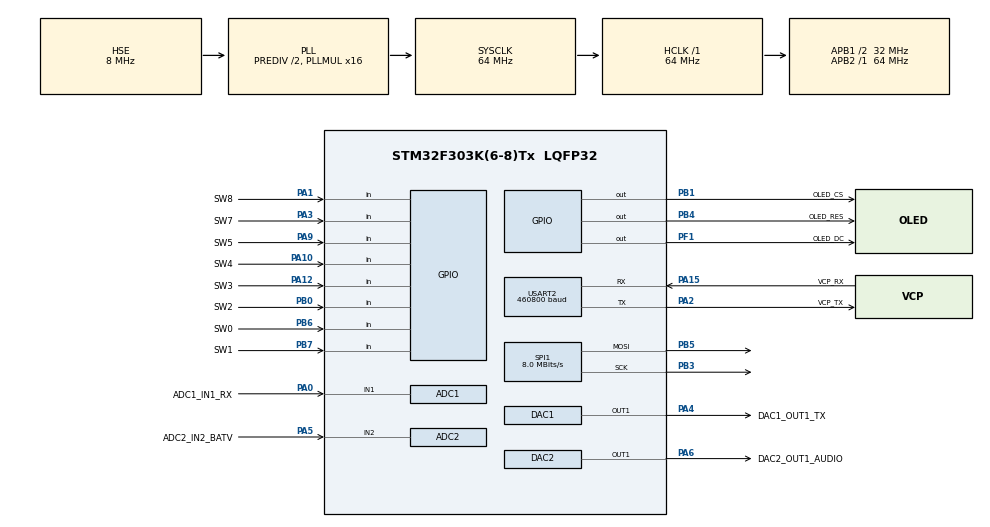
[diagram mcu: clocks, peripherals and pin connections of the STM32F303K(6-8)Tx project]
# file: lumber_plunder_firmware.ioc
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ADC1.Channel-0\#ChannelRegularConversion=ADC_CHANNEL_1
ADC1.Channel-1\#ChannelRegularConversion=ADC_CHANNEL_1
ADC1.Channel-10\#ChannelRegularConversion=ADC_CHANNEL_1
ADC1.Channel-11\#ChannelRegularConversion=ADC_CHANNEL_1
ADC1.Channel-12\#ChannelRegularConversion=ADC_CHANNEL_1
ADC1.Channel-13\#ChannelRegularConversion=ADC_CHANNEL_1
ADC1.Channel-14\#ChannelRegularConversion=ADC_CHANNEL_1
ADC1.Channel-15\#ChannelRegularConversion=ADC_CHANNEL_1
ADC1.Channel-2\#ChannelRegularConversion=ADC_CHANNEL_1
ADC1.Channel-3\#ChannelRegularConversion=ADC_CHANNEL_1
ADC1.Channel-4\#ChannelRegularConversion=ADC_CHANNEL_1
ADC1.Channel-5\#ChannelRegularConversion=ADC_CHANNEL_1
ADC1.Channel-6\#ChannelRegularConversion=ADC_CHANNEL_1
ADC1.Channel-7\#ChannelRegularConversion=ADC_CHANNEL_1
ADC1.Channel-8\#ChannelRegularConversion=ADC_CHANNEL_1
ADC1.Channel-9\#ChannelRegularConversion=ADC_CHANNEL_1
ADC1.NbrOfConversion=16
ADC1.NbrOfConversionFlag=1
ADC1.Offset-0\#ChannelRegularConversion=0
ADC1.Offset-1\#ChannelRegularConversion=0
ADC1.Offset-10\#ChannelRegularConversion=0
ADC1.Offset-11\#ChannelRegularConversion=0
ADC1.Offset-12\#ChannelRegularConversion=0
ADC1.Offset-13\#ChannelRegularConversion=0
ADC1.Offset-14\#ChannelRegularConversion=0
ADC1.Offset-15\#ChannelRegularConversion=0
ADC1.Offset-2\#ChannelRegularConversion=0
ADC1.Offset-3\#ChannelRegularConversion=0
ADC1.Offset-4\#ChannelRegularConversion=0
ADC1.Offset-5\#ChannelRegularConversion=0
ADC1.Offset-6\#ChannelRegularConversion=0
ADC1.Offset-7\#ChannelRegularConversion=0
ADC1.Offset-8\#ChannelRegularConversion=0
ADC1.Offset-9\#ChannelRegularConversion=0
ADC1.OffsetNumber-0\#ChannelRegularConversion=ADC_OFFSET_NONE
ADC1.OffsetNumber-1\#ChannelRegularConversion=ADC_OFFSET_NONE
ADC1.OffsetNumber-10\#ChannelRegularConversion=ADC_OFFSET_NONE
ADC1.OffsetNumber-11\#ChannelRegularConversion=ADC_OFFSET_NONE
ADC1.OffsetNumber-12\#ChannelRegularConversion=ADC_OFFSET_NONE
ADC1.OffsetNumber-13\#ChannelRegularConversion=ADC_OFFSET_NONE
ADC1.OffsetNumber-14\#ChannelRegularConversion=ADC_OFFSET_NONE
ADC1.OffsetNumber-15\#ChannelRegularConversion=ADC_OFFSET_NONE
ADC1.OffsetNumber-2\#ChannelRegularConversion=ADC_OFFSET_NONE
ADC1.OffsetNumber-3\#ChannelRegularConversion=ADC_OFFSET_NONE
ADC1.OffsetNumber-4\#ChannelRegularConversion=ADC_OFFSET_NONE
ADC1.OffsetNumber-5\#ChannelRegularConversion=ADC_OFFSET_NONE
ADC1.OffsetNumber-6\#ChannelRegularConversion=ADC_OFFSET_NONE
ADC1.OffsetNumber-7\#ChannelRegularConversion=ADC_OFFSET_NONE
ADC1.OffsetNumber-8\#ChannelRegularConversion=ADC_OFFSET_NONE
ADC1.OffsetNumber-9\#ChannelRegularConversion=ADC_OFFSET_NONE
ADC1.Rank-0\#ChannelRegularConversion=1
ADC1.Rank-1\#ChannelRegularConversion=2
ADC1.Rank-10\#ChannelRegularConversion=11
ADC1.Rank-11\#ChannelRegularConversion=12
ADC1.Rank-12\#ChannelRegularConversion=13
ADC1.Rank-13\#ChannelRegularConversion=14
ADC1.Rank-14\#ChannelRegularConversion=15
ADC1.Rank-15\#ChannelRegularConversion=16
ADC1.Rank-2\#ChannelRegularConversion=3
ADC1.Rank-3\#ChannelRegularConversion=4
ADC1.Rank-4\#ChannelRegularConversion=5
ADC1.Rank-5\#ChannelRegularConversion=6
ADC1.Rank-6\#ChannelRegularConversion=7
ADC1.Rank-7\#ChannelRegularConversion=8
ADC1.Rank-8\#ChannelRegularConversion=9
ADC1.Rank-9\#ChannelRegularConversion=10
ADC1.SamplingTime-0\#ChannelRegularConversion=ADC_SAMPLETIME_1CYCLE_5
ADC1.SamplingTime-1\#ChannelRegularConversion=ADC_SAMPLETIME_1CYCLE_5
ADC1.SamplingTime-10\#ChannelRegularConversion=ADC_SAMPLETIME_1CYCLE_5
ADC1.SamplingTime-11\#ChannelRegularConversion=ADC_SAMPLETIME_1CYCLE_5
ADC1.SamplingTime-12\#ChannelRegularConversion=ADC_SAMPLETIME_1CYCLE_5
ADC1.SamplingTime-13\#ChannelRegularConversion=ADC_SAMPLETIME_1CYCLE_5
ADC1.SamplingTime-14\#ChannelRegularConversion=ADC_SAMPLETIME_1CYCLE_5
ADC1.SamplingTime-15\#ChannelRegularConversion=ADC_SAMPLETIME_1CYCLE_5
ADC1.SamplingTime-2\#ChannelRegularConversion=ADC_SAMPLETIME_1CYCLE_5
ADC1.SamplingTime-3\#ChannelRegularConversion=ADC_SAMPLETIME_1CYCLE_5
ADC1.SamplingTime-4\#ChannelRegularConversion=ADC_SAMPLETIME_1CYCLE_5
ADC1.SamplingTime-5\#ChannelRegularConversion=ADC_SAMPLETIME_1CYCLE_5
ADC1.SamplingTime-6\#ChannelRegularConversion=ADC_SAMPLETIME_1CYCLE_5
ADC1.SamplingTime-7\#ChannelRegularConversion=ADC_SAMPLETIME_1CYCLE_5
ADC1.SamplingTime-8\#ChannelRegularConversion=ADC_SAMPLETIME_1CYCLE_5
ADC1.SamplingTime-9\#ChannelRegularConversion=ADC_SAMPLETIME_1CYCLE_5
ADC1.SamplingTimeOPAMP-0\#ChannelRegularConversion=ADC_SAMPLETIME_19CYCLES_5
ADC1.SamplingTimeOPAMP-1\#ChannelRegularConversion=ADC_SAMPLETIME_1CYCLE_5
ADC1.SamplingTimeOPAMP-10\#ChannelRegularConversion=ADC_SAMPLETIME_1CYCLE_5
ADC1.SamplingTimeOPAMP-11\#ChannelRegularConversion=ADC_SAMPLETIME_1CYCLE_5
ADC1.SamplingTimeOPAMP-12\#ChannelRegularConversion=ADC_SAMPLETIME_1CYCLE_5
ADC1.SamplingTimeOPAMP-13\#ChannelRegularConversion=ADC_SAMPLETIME_1CYCLE_5
ADC1.SamplingTimeOPAMP-14\#ChannelRegularConversion=ADC_SAMPLETIME_1CYCLE_5
ADC1.SamplingTimeOPAMP-15\#ChannelRegularConversion=ADC_SAMPLETIME_1CYCLE_5
ADC1.SamplingTimeOPAMP-2\#ChannelRegularConversion=ADC_SAMPLETIME_1CYCLE_5
ADC1.SamplingTimeOPAMP-3\#ChannelRegularConversion=ADC_SAMPLETIME_1CYCLE_5
ADC1.SamplingTimeOPAMP-4\#ChannelRegularConversion=ADC_SAMPLETIME_1CYCLE_5
ADC1.SamplingTimeOPAMP-5\#ChannelRegularConversion=ADC_SAMPLETIME_1CYCLE_5
ADC1.SamplingTimeOPAMP-6\#ChannelRegularConversion=ADC_SAMPLETIME_1CYCLE_5
ADC1.SamplingTimeOPAMP-7\#ChannelRegularConversion=ADC_SAMPLETIME_1CYCLE_5
ADC1.SamplingTimeOPAMP-8\#ChannelRegularConversion=ADC_SAMPLETIME_1CYCLE_5
ADC1.SamplingTimeOPAMP-9\#ChannelRegularConversion=ADC_SAMPLETIME_1CYCLE_5
ADC1.SubFamily=STM32F303x8
ADC1.master=1
ADC2.Channel-17\#ChannelRegularConversion=ADC_CHANNEL_2
ADC2.NbrOfConversionFlag=1
ADC2.Offset-17\#ChannelRegularConversion=0
ADC2.OffsetNumber-17\#ChannelRegularConversion=ADC_OFFSET_NONE
ADC2.Rank-17\#ChannelRegularConversion=1
ADC2.SamplingTime-17\#ChannelRegularConversion=ADC_SAMPLETIME_1CYCLE_5
ADC2.SamplingTimeOPAMP-17\#ChannelRegularConversion=ADC_SAMPLETIME_1CYCLE_5
ADC2.SubFamily=STM32F303x8
DAC1.DAC_OutputBuffer=DAC_OUTPUTBUFFER_ENABLE
Dma.DAC1_CH1.0.Direction=DMA_MEMORY_TO_PERIPH
Dma.DAC1_CH1.0.Instance=DMA1_Channel3
Dma.DAC1_CH1.0.MemDataAlignment=DMA_MDATAALIGN_HALFWORD
Dma.DAC1_CH1.0.MemInc=DMA_MINC_ENABLE
Dma.DAC1_CH1.0.Mode=DMA_CIRCULAR
Dma.DAC1_CH1.0.PeriphDataAlignment=DMA_PDATAALIGN_HALFWORD
Dma.DAC1_CH1.0.PeriphInc=DMA_PINC_DISABLE
Dma.DAC1_CH1.0.Priority=DMA_PRIORITY_HIGH
Dma.Request0=DAC1_CH1
Mcu.Family=STM32F3
Mcu.Name=STM32F303K(6-8)Tx
Mcu.Package=LQFP32
NVIC.DMA1_Channel3_IRQn=true\:0\:0\:false\:false\:true\:false\:true\:true
NVIC.PriorityGroup=NVIC_PRIORITYGROUP_4
PA0.GPIO_Label=ADC1_IN1_RX
PA0.Mode=IN1-Single-Ended
PA0.Signal=ADC1_IN1
PA1.GPIO_Label=SW8
PA1.Signal=GPIO_Input
PA10.GPIO_Label=SW4
PA10.Signal=GPIO_Input
PA12.GPIO_Label=SW3
PA12.Signal=GPIO_Input
PA13.GPIO_Label=SWDIO
PA13.Mode=Serial_Wire
PA13.Signal=SYS_JTMS-SWDIO
PA14.GPIO_Label=SWCLK
PA14.Mode=Serial_Wire
PA14.Signal=SYS_JTCK-SWCLK
PA15.GPIO_Label=VCP_RX
PA15.Mode=Asynchronous
PA15.Signal=USART2_RX
PA2.GPIO_Label=VCP_TX
PA2.Mode=Asynchronous
PA2.Signal=USART2_TX
PA3.GPIO_Label=SW7
PA3.Signal=GPIO_Input
PA4.GPIO_Label=DAC1_OUT1_TX
PA4.Signal=COMP_DAC11_group
PA5.GPIO_Label=ADC2_IN2_BATV
PA5.Mode=IN2-Single-Ended
PA5.Signal=ADC2_IN2
PA6.GPIO_Label=DAC2_OUT1_AUDIO
PA6.Signal=COMP_DAC21_group
PA7.Signal=ADC2_IN4
PA9.GPIO_Label=SW5
PA9.Signal=GPIO_Input
PB0.GPIO_Label=SW2
PB0.Signal=GPIO_Input
PB1.GPIO_Label=OLED_CS
PB1.Signal=GPIO_Output
PB3.Mode=TX_Only_Simplex_Unidirect_Master
PB3.Signal=SPI1_SCK
PB4.GPIO_Label=OLED_RES
PB4.Signal=GPIO_Output
PB5.Mode=TX_Only_Simplex_Unidirect_Master
PB5.Signal=SPI1_MOSI
PB6.GPIO_Label=SW0
PB6.Signal=GPIO_Input
PB7.GPIO_Label=SW1
PB7.Signal=GPIO_Input
PF0\ /\ OSC_IN.GPIO_Label=MCO
PF0\ /\ OSC_IN.Mode=HSE-External-Clock-Source
PF0\ /\ OSC_IN.Signal=RCC_OSC_IN
PF1\ /\ OSC_OUT.GPIO_Label=OLED_DC
PF1\ /\ OSC_OUT.Signal=GPIO_Output
ProjectManager.HeapSize=0x200
ProjectManager.StackSize=0x400
ProjectManager.TargetToolchain=STM32CubeIDE
RCC.ADC12PRES=RCC_ADC12PLLCLK_DIV64
RCC.AHBFreq_Value=64000000
RCC.APB1CLKDivider=RCC_HCLK_DIV2
RCC.APB1Freq_Value=32000000
RCC.APB1TimFreq_Value=64000000
RCC.APB2Freq_Value=64000000
RCC.APB2TimFreq_Value=64000000
RCC.CortexFreq_Value=64000000
RCC.HCLKFreq_Value=64000000
RCC.HSE_VALUE=8000000
RCC.HSI_VALUE=8000000
RCC.PLLMUL=RCC_PLL_MUL16
RCC.PLLSourceVirtual=RCC_PLLSOURCE_HSE
RCC.RCC_PLLsource_Clock_Source_FROM_HSE=RCC_HSE_PREDIV_DIV2
RCC.SYSCLKFreq_VALUE=64000000
RCC.SYSCLKSourceVirtual=RCC_SYSCLKSOURCE_PLLCLK
SH.COMP_DAC11_group.0=DAC1_OUT1,DAC_OUT1
SH.COMP_DAC21_group.0=DAC2_OUT1,Switch_Enable_OUT1
SPI1.BaudRatePrescaler=SPI_BAUDRATEPRESCALER_8
SPI1.CLKPhase=SPI_PHASE_1EDGE
SPI1.CLKPolarity=SPI_POLARITY_LOW
SPI1.CalculateBaudRate=8.0 MBits/s
SPI1.DataSize=SPI_DATASIZE_8BIT
SPI1.Direction=SPI_DIRECTION_2LINES
SPI1.FirstBit=SPI_FIRSTBIT_MSB
SPI1.Mode=SPI_MODE_MASTER
SPI1.VirtualType=VM_MASTER
USART2.BaudRate=460800
USART2.VirtualMode-Asynchronous=VM_ASYNC
board=NUCLEO-F303K8

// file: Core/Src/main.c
/* USER CODE BEGIN Header */
/**
  ******************************************************************************
  * @file           : main.c
  * @brief          : Main program body
  ******************************************************************************
  * @attention
  *
  * Copyright (c) 2023 STMicroelectronics.
  * All rights reserved.
  *
  * This software is licensed under terms that can be found in the LICENSE file
  * in the root directory of this software component.
  * If no LICENSE file comes with this software, it is provided AS-IS.
  *
  ******************************************************************************
  */
/* USER CODE END Header */
#include "main.h"

ADC_HandleTypeDef hadc1;

DAC_HandleTypeDef hdac1;
DAC_HandleTypeDef hdac2;
DMA_HandleTypeDef hdma_dac1_ch1;

SPI_HandleTypeDef hspi1;

UART_HandleTypeDef huart2;

void SystemClock_Config(void);
static void MX_GPIO_Init(void);
static void MX_DMA_Init(void);
static void MX_USART2_UART_Init(void);
static void MX_ADC1_Init(void);
static void MX_SPI1_Init(void);
static void MX_ADC2_Init(void);
static void MX_DAC1_Init(void);
static void MX_DAC2_Init(void);

int main(void)
{

  /* MCU Configuration--------------------------------------------------------*/

  /* Reset of all peripherals, Initializes the Flash interface and the Systick. */
  HAL_Init();

  /* Configure the system clock */
  SystemClock_Config();

  /* Initialize all configured peripherals */
  MX_GPIO_Init();
  MX_DMA_Init();
  MX_USART2_UART_Init();
  MX_ADC1_Init();
  MX_SPI1_Init();
  MX_ADC2_Init();
  MX_DAC1_Init();
  MX_DAC2_Init();
  /* USER CODE BEGIN 2 */

  //The only non-generated code in this file... everything else is handled in maincpp.c
  maincpp();

  /* USER CODE END 2 */

  /* Infinite loop */

}

void SystemClock_Config(void)
{
  RCC_OscInitTypeDef RCC_OscInitStruct = {0};
  RCC_ClkInitTypeDef RCC_ClkInitStruct = {0};
  RCC_PeriphCLKInitTypeDef PeriphClkInit = {0};

  /** Initializes the RCC Oscillators according to the specified parameters
  * in the RCC_OscInitTypeDef structure.
  */
  RCC_OscInitStruct.OscillatorType = RCC_OSCILLATORTYPE_HSE;
  RCC_OscInitStruct.HSEState = RCC_HSE_BYPASS;
  RCC_OscInitStruct.HSEPredivValue = RCC_HSE_PREDIV_DIV2;
  RCC_OscInitStruct.HSIState = RCC_HSI_ON;
  RCC_OscInitStruct.PLL.PLLState = RCC_PLL_ON;
  RCC_OscInitStruct.PLL.PLLSource = RCC_PLLSOURCE_HSE;
  RCC_OscInitStruct.PLL.PLLMUL = RCC_PLL_MUL16;
  if (HAL_RCC_OscConfig(&RCC_OscInitStruct) != HAL_OK)
  {
    Error_Handler();
  }

  /** Initializes the CPU, AHB and APB buses clocks
  */
  RCC_ClkInitStruct.ClockType = RCC_CLOCKTYPE_HCLK|RCC_CLOCKTYPE_SYSCLK
                              |RCC_CLOCKTYPE_PCLK1|RCC_CLOCKTYPE_PCLK2;
  RCC_ClkInitStruct.SYSCLKSource = RCC_SYSCLKSOURCE_PLLCLK;
  RCC_ClkInitStruct.AHBCLKDivider = RCC_SYSCLK_DIV1;
  RCC_ClkInitStruct.APB1CLKDivider = RCC_HCLK_DIV2;
  RCC_ClkInitStruct.APB2CLKDivider = RCC_HCLK_DIV1;

  if (HAL_RCC_ClockConfig(&RCC_ClkInitStruct, FLASH_LATENCY_2) != HAL_OK)
  {
    Error_Handler();
  }
  PeriphClkInit.PeriphClockSelection = RCC_PERIPHCLK_ADC12;
  PeriphClkInit.Adc12ClockSelection = RCC_ADC12PLLCLK_DIV64;
  if (HAL_RCCEx_PeriphCLKConfig(&PeriphClkInit) != HAL_OK)
  {
    Error_Handler();
  }
}

static void MX_ADC1_Init(void)
{

  ADC_MultiModeTypeDef multimode = {0};
  ADC_ChannelConfTypeDef sConfig = {0};

  /** Common config
  */
  hadc1.Instance = ADC1;
  hadc1.Init.ClockPrescaler = ADC_CLOCK_ASYNC_DIV1;
  hadc1.Init.Resolution = ADC_RESOLUTION_12B;
  hadc1.Init.ScanConvMode = ADC_SCAN_ENABLE;
  hadc1.Init.ContinuousConvMode = DISABLE;
  hadc1.Init.DiscontinuousConvMode = DISABLE;
  hadc1.Init.ExternalTrigConvEdge = ADC_EXTERNALTRIGCONVEDGE_NONE;
  hadc1.Init.ExternalTrigConv = ADC_SOFTWARE_START;
  hadc1.Init.DataAlign = ADC_DATAALIGN_RIGHT;
  hadc1.Init.NbrOfConversion = 16;
  hadc1.Init.DMAContinuousRequests = DISABLE;
  hadc1.Init.EOCSelection = ADC_EOC_SINGLE_CONV;
  hadc1.Init.LowPowerAutoWait = DISABLE;
  hadc1.Init.Overrun = ADC_OVR_DATA_OVERWRITTEN;
  if (HAL_ADC_Init(&hadc1) != HAL_OK)
  {
    Error_Handler();
  }

  /** Configure the ADC multi-mode
  */
  multimode.Mode = ADC_MODE_INDEPENDENT;
  if (HAL_ADCEx_MultiModeConfigChannel(&hadc1, &multimode) != HAL_OK)
  {
    Error_Handler();
  }

  /** Configure Regular Channel
  */
  sConfig.Channel = ADC_CHANNEL_1;
  sConfig.Rank = ADC_REGULAR_RANK_1;
  sConfig.SingleDiff = ADC_SINGLE_ENDED;
  sConfig.SamplingTime = ADC_SAMPLETIME_1CYCLE_5;
  sConfig.OffsetNumber = ADC_OFFSET_NONE;
  sConfig.Offset = 0;
  if (HAL_ADC_ConfigChannel(&hadc1, &sConfig) != HAL_OK)
  {
    Error_Handler();
  }

  /** Configure Regular Channel
  */
  sConfig.Rank = ADC_REGULAR_RANK_2;
  if (HAL_ADC_ConfigChannel(&hadc1, &sConfig) != HAL_OK)
  {
    Error_Handler();
  }

  /** Configure Regular Channel
  */
  sConfig.Rank = ADC_REGULAR_RANK_3;
  if (HAL_ADC_ConfigChannel(&hadc1, &sConfig) != HAL_OK)
  {
    Error_Handler();
  }

  /** Configure Regular Channel
  */
  sConfig.Rank = ADC_REGULAR_RANK_4;
  if (HAL_ADC_ConfigChannel(&hadc1, &sConfig) != HAL_OK)
  {
    Error_Handler();
  }

  /** Configure Regular Channel
  */
  sConfig.Rank = ADC_REGULAR_RANK_5;
  if (HAL_ADC_ConfigChannel(&hadc1, &sConfig) != HAL_OK)
  {
    Error_Handler();
  }

  /** Configure Regular Channel
  */
  sConfig.Rank = ADC_REGULAR_RANK_6;
  if (HAL_ADC_ConfigChannel(&hadc1, &sConfig) != HAL_OK)
  {
    Error_Handler();
  }

  /** Configure Regular Channel
  */
  sConfig.Rank = ADC_REGULAR_RANK_7;
  if (HAL_ADC_ConfigChannel(&hadc1, &sConfig) != HAL_OK)
  {
    Error_Handler();
  }

  /** Configure Regular Channel
  */
  sConfig.Rank = ADC_REGULAR_RANK_8;
  if (HAL_ADC_ConfigChannel(&hadc1, &sConfig) != HAL_OK)
  {
    Error_Handler();
  }

  /** Configure Regular Channel
  */
  sConfig.Rank = ADC_REGULAR_RANK_9;
  if (HAL_ADC_ConfigChannel(&hadc1, &sConfig) != HAL_OK)
  {
    Error_Handler();
  }

  /** Configure Regular Channel
  */
  sConfig.Rank = ADC_REGULAR_RANK_10;
  if (HAL_ADC_ConfigChannel(&hadc1, &sConfig) != HAL_OK)
  {
    Error_Handler();
  }

  /** Configure Regular Channel
  */
  sConfig.Rank = ADC_REGULAR_RANK_11;
  if (HAL_ADC_ConfigChannel(&hadc1, &sConfig) != HAL_OK)
  {
    Error_Handler();
  }

  /** Configure Regular Channel
  */
  sConfig.Rank = ADC_REGULAR_RANK_12;
  if (HAL_ADC_ConfigChannel(&hadc1, &sConfig) != HAL_OK)
  {
    Error_Handler();
  }

  /** Configure Regular Channel
  */
  sConfig.Rank = ADC_REGULAR_RANK_13;
  if (HAL_ADC_ConfigChannel(&hadc1, &sConfig) != HAL_OK)
  {
    Error_Handler();
  }

  /** Configure Regular Channel
  */
  sConfig.Rank = ADC_REGULAR_RANK_14;
  if (HAL_ADC_ConfigChannel(&hadc1, &sConfig) != HAL_OK)
  {
    Error_Handler();
  }

  /** Configure Regular Channel
  */
  sConfig.Rank = ADC_REGULAR_RANK_15;
  if (HAL_ADC_ConfigChannel(&hadc1, &sConfig) != HAL_OK)
  {
    Error_Handler();
  }

  /** Configure Regular Channel
  */
  sConfig.Rank = ADC_REGULAR_RANK_16;
  if (HAL_ADC_ConfigChannel(&hadc1, &sConfig) != HAL_OK)
  {
    Error_Handler();
  }

}

static void MX_ADC2_Init(void)
{

  LL_ADC_InitTypeDef ADC_InitStruct = {0};
  LL_ADC_REG_InitTypeDef ADC_REG_InitStruct = {0};

  LL_GPIO_InitTypeDef GPIO_InitStruct = {0};

  /* Peripheral clock enable */
  LL_AHB1_GRP1_EnableClock(LL_AHB1_GRP1_PERIPH_ADC12);

  LL_AHB1_GRP1_EnableClock(LL_AHB1_GRP1_PERIPH_GPIOA);
  /**ADC2 GPIO Configuration
  PA5   ------> ADC2_IN2
  PA7   ------> ADC2_IN4
  */
  GPIO_InitStruct.Pin = LL_GPIO_PIN_5|LL_GPIO_PIN_7;
  GPIO_InitStruct.Mode = LL_GPIO_MODE_ANALOG;
  GPIO_InitStruct.Pull = LL_GPIO_PULL_NO;
  LL_GPIO_Init(GPIOA, &GPIO_InitStruct);

  /** Common config
  */
  ADC_InitStruct.Resolution = LL_ADC_RESOLUTION_12B;
  ADC_InitStruct.DataAlignment = LL_ADC_DATA_ALIGN_RIGHT;
  ADC_InitStruct.LowPowerMode = LL_ADC_LP_MODE_NONE;
  LL_ADC_Init(ADC2, &ADC_InitStruct);
  ADC_REG_InitStruct.TriggerSource = LL_ADC_REG_TRIG_SOFTWARE;
  ADC_REG_InitStruct.SequencerLength = LL_ADC_REG_SEQ_SCAN_DISABLE;
  ADC_REG_InitStruct.SequencerDiscont = LL_ADC_REG_SEQ_DISCONT_DISABLE;
  ADC_REG_InitStruct.ContinuousMode = LL_ADC_REG_CONV_SINGLE;
  ADC_REG_InitStruct.DMATransfer = LL_ADC_REG_DMA_TRANSFER_LIMITED;
  ADC_REG_InitStruct.Overrun = LL_ADC_REG_OVR_DATA_OVERWRITTEN;
  LL_ADC_REG_Init(ADC2, &ADC_REG_InitStruct);

  /* Enable ADC internal voltage regulator */
  LL_ADC_EnableInternalRegulator(ADC2);
  /* Delay for ADC internal voltage regulator stabilization. */
  /* Compute number of CPU cycles to wait for, from delay in us. */
  /* Note: Variable divided by 2 to compensate partially */
  /* CPU processing cycles (depends on compilation optimization). */
  /* Note: If system core clock frequency is below 200kHz, wait time */
  /* is only a few CPU processing cycles. */
  uint32_t wait_loop_index;
  wait_loop_index = ((LL_ADC_DELAY_INTERNAL_REGUL_STAB_US * (SystemCoreClock / (100000 * 2))) / 10);
  while(wait_loop_index != 0)
  {
    wait_loop_index--;
  }

  /** Configure Regular Channel
  */
  LL_ADC_REG_SetSequencerRanks(ADC2, LL_ADC_REG_RANK_1, LL_ADC_CHANNEL_2);
  LL_ADC_SetChannelSamplingTime(ADC2, LL_ADC_CHANNEL_2, LL_ADC_SAMPLINGTIME_1CYCLE_5);
  LL_ADC_SetChannelSingleDiff(ADC2, LL_ADC_CHANNEL_2, LL_ADC_SINGLE_ENDED);

}

static void MX_DAC1_Init(void)
{

  DAC_ChannelConfTypeDef sConfig = {0};

  /** DAC Initialization
  */
  hdac1.Instance = DAC1;
  if (HAL_DAC_Init(&hdac1) != HAL_OK)
  {
    Error_Handler();
  }

  /** DAC channel OUT1 config
  */
  sConfig.DAC_Trigger = DAC_TRIGGER_NONE;
  sConfig.DAC_OutputBuffer = DAC_OUTPUTBUFFER_ENABLE;
  if (HAL_DAC_ConfigChannel(&hdac1, &sConfig, DAC_CHANNEL_1) != HAL_OK)
  {
    Error_Handler();
  }

}

static void MX_DAC2_Init(void)
{

  DAC_ChannelConfTypeDef sConfig = {0};

  /** DAC Initialization
  */
  hdac2.Instance = DAC2;
  if (HAL_DAC_Init(&hdac2) != HAL_OK)
  {
    Error_Handler();
  }

  /** DAC channel OUT1 config
  */
  sConfig.DAC_Trigger = DAC_TRIGGER_NONE;
  sConfig.DAC_OutputSwitch = DAC_OUTPUTSWITCH_ENABLE;
  if (HAL_DAC_ConfigChannel(&hdac2, &sConfig, DAC_CHANNEL_1) != HAL_OK)
  {
    Error_Handler();
  }

}

static void MX_SPI1_Init(void)
{

  /* SPI1 parameter configuration*/
  hspi1.Instance = SPI1;
  hspi1.Init.Mode = SPI_MODE_MASTER;
  hspi1.Init.Direction = SPI_DIRECTION_2LINES;
  hspi1.Init.DataSize = SPI_DATASIZE_8BIT;
  hspi1.Init.CLKPolarity = SPI_POLARITY_LOW;
  hspi1.Init.CLKPhase = SPI_PHASE_1EDGE;
  hspi1.Init.NSS = SPI_NSS_SOFT;
  hspi1.Init.BaudRatePrescaler = SPI_BAUDRATEPRESCALER_8;
  hspi1.Init.FirstBit = SPI_FIRSTBIT_MSB;
  hspi1.Init.TIMode = SPI_TIMODE_DISABLE;
  hspi1.Init.CRCCalculation = SPI_CRCCALCULATION_DISABLE;
  hspi1.Init.CRCPolynomial = 7;
  hspi1.Init.CRCLength = SPI_CRC_LENGTH_DATASIZE;
  hspi1.Init.NSSPMode = SPI_NSS_PULSE_ENABLE;
  if (HAL_SPI_Init(&hspi1) != HAL_OK)
  {
    Error_Handler();
  }

}

static void MX_USART2_UART_Init(void)
{

  huart2.Instance = USART2;
  huart2.Init.BaudRate = 460800;
  huart2.Init.WordLength = UART_WORDLENGTH_8B;
  huart2.Init.StopBits = UART_STOPBITS_1;
  huart2.Init.Parity = UART_PARITY_NONE;
  huart2.Init.Mode = UART_MODE_TX_RX;
  huart2.Init.HwFlowCtl = UART_HWCONTROL_NONE;
  huart2.Init.OverSampling = UART_OVERSAMPLING_16;
  huart2.Init.OneBitSampling = UART_ONE_BIT_SAMPLE_DISABLE;
  huart2.AdvancedInit.AdvFeatureInit = UART_ADVFEATURE_NO_INIT;
  if (HAL_UART_Init(&huart2) != HAL_OK)
  {
    Error_Handler();
  }

}

static void MX_DMA_Init(void)
{

  /* DMA controller clock enable */
  __HAL_RCC_DMA1_CLK_ENABLE();

  /* DMA interrupt init */
  /* DMA1_Channel3_IRQn interrupt configuration */
  HAL_NVIC_SetPriority(DMA1_Channel3_IRQn, 0, 0);
  HAL_NVIC_EnableIRQ(DMA1_Channel3_IRQn);

}

static void MX_GPIO_Init(void)
{
  GPIO_InitTypeDef GPIO_InitStruct = {0};

  /* GPIO Ports Clock Enable */
  __HAL_RCC_GPIOF_CLK_ENABLE();
  __HAL_RCC_GPIOA_CLK_ENABLE();
  __HAL_RCC_GPIOB_CLK_ENABLE();

  /*Configure GPIO pin Output Level */
  HAL_GPIO_WritePin(OLED_DC_GPIO_Port, OLED_DC_Pin, GPIO_PIN_RESET);

  /*Configure GPIO pin Output Level */
  HAL_GPIO_WritePin(GPIOB, OLED_CS_Pin|OLED_RES_Pin, GPIO_PIN_RESET);

  /*Configure GPIO pin : OLED_DC_Pin */
  GPIO_InitStruct.Pin = OLED_DC_Pin;
  GPIO_InitStruct.Mode = GPIO_MODE_OUTPUT_PP;
  GPIO_InitStruct.Pull = GPIO_NOPULL;
  GPIO_InitStruct.Speed = GPIO_SPEED_FREQ_LOW;
  HAL_GPIO_Init(OLED_DC_GPIO_Port, &GPIO_InitStruct);

  /*Configure GPIO pins : SW8_Pin SW7_Pin SW5_Pin SW4_Pin
                           SW3_Pin */
  GPIO_InitStruct.Pin = SW8_Pin|SW7_Pin|SW5_Pin|SW4_Pin
                          |SW3_Pin;
  GPIO_InitStruct.Mode = GPIO_MODE_INPUT;
  GPIO_InitStruct.Pull = GPIO_NOPULL;
  HAL_GPIO_Init(GPIOA, &GPIO_InitStruct);

  /*Configure GPIO pins : SW2_Pin SW0_Pin SW1_Pin */
  GPIO_InitStruct.Pin = SW2_Pin|SW0_Pin|SW1_Pin;
  GPIO_InitStruct.Mode = GPIO_MODE_INPUT;
  GPIO_InitStruct.Pull = GPIO_NOPULL;
  HAL_GPIO_Init(GPIOB, &GPIO_InitStruct);

  /*Configure GPIO pins : OLED_CS_Pin OLED_RES_Pin */
  GPIO_InitStruct.Pin = OLED_CS_Pin|OLED_RES_Pin;
  GPIO_InitStruct.Mode = GPIO_MODE_OUTPUT_PP;
  GPIO_InitStruct.Pull = GPIO_NOPULL;
  GPIO_InitStruct.Speed = GPIO_SPEED_FREQ_LOW;
  HAL_GPIO_Init(GPIOB, &GPIO_InitStruct);

}

void Error_Handler(void)
{
  __disable_irq();
  while (1)
  {
  }
}
